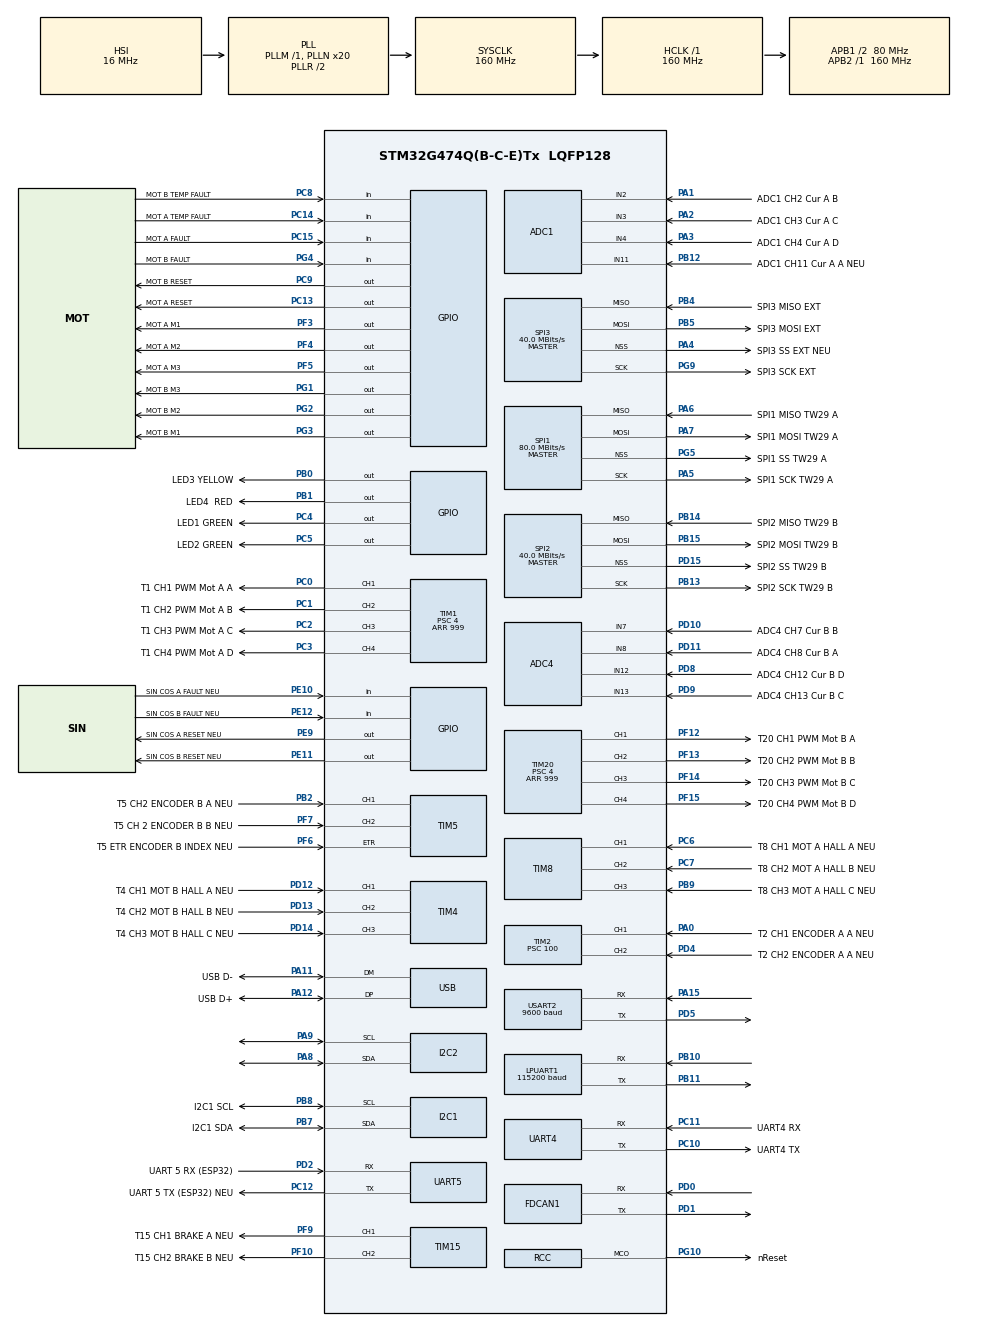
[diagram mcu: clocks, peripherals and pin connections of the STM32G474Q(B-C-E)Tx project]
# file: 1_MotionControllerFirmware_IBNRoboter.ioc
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ADC1.Channel-0\#ChannelRegularConversion=ADC_CHANNEL_2
ADC1.NbrOfConversionFlag=1
ADC1.OffsetNumber-0\#ChannelRegularConversion=ADC_OFFSET_NONE
ADC1.Rank-0\#ChannelRegularConversion=1
ADC1.SamplingTime-0\#ChannelRegularConversion=ADC_SAMPLETIME_2CYCLES_5
ADC1.master=1
ADC4.Channel-1\#ChannelRegularConversion=ADC_CHANNEL_12
ADC4.NbrOfConversionFlag=1
ADC4.OffsetNumber-1\#ChannelRegularConversion=ADC_OFFSET_NONE
ADC4.Rank-1\#ChannelRegularConversion=1
ADC4.SamplingTime-1\#ChannelRegularConversion=ADC_SAMPLETIME_2CYCLES_5
Dma.LPUART1_RX.0.Direction=DMA_PERIPH_TO_MEMORY
Dma.LPUART1_RX.0.EventEnable=DISABLE
Dma.LPUART1_RX.0.Instance=DMA1_Channel1
Dma.LPUART1_RX.0.MemDataAlignment=DMA_MDATAALIGN_BYTE
Dma.LPUART1_RX.0.MemInc=DMA_MINC_ENABLE
Dma.LPUART1_RX.0.Mode=DMA_NORMAL
Dma.LPUART1_RX.0.PeriphDataAlignment=DMA_PDATAALIGN_BYTE
Dma.LPUART1_RX.0.PeriphInc=DMA_PINC_DISABLE
Dma.LPUART1_RX.0.Polarity=HAL_DMAMUX_REQ_GEN_RISING
Dma.LPUART1_RX.0.Priority=DMA_PRIORITY_LOW
Dma.LPUART1_RX.0.RequestNumber=1
Dma.LPUART1_RX.0.SignalID=NONE
Dma.LPUART1_RX.0.SyncEnable=DISABLE
Dma.LPUART1_RX.0.SyncPolarity=HAL_DMAMUX_SYNC_NO_EVENT
Dma.LPUART1_RX.0.SyncRequestNumber=1
Dma.LPUART1_RX.0.SyncSignalID=NONE
Dma.LPUART1_TX.1.Direction=DMA_MEMORY_TO_PERIPH
Dma.LPUART1_TX.1.EventEnable=DISABLE
Dma.LPUART1_TX.1.Instance=DMA1_Channel2
Dma.LPUART1_TX.1.MemDataAlignment=DMA_MDATAALIGN_BYTE
Dma.LPUART1_TX.1.MemInc=DMA_MINC_ENABLE
Dma.LPUART1_TX.1.Mode=DMA_NORMAL
Dma.LPUART1_TX.1.PeriphDataAlignment=DMA_PDATAALIGN_BYTE
Dma.LPUART1_TX.1.PeriphInc=DMA_PINC_DISABLE
Dma.LPUART1_TX.1.Polarity=HAL_DMAMUX_REQ_GEN_RISING
Dma.LPUART1_TX.1.Priority=DMA_PRIORITY_LOW
Dma.LPUART1_TX.1.RequestNumber=1
Dma.LPUART1_TX.1.SignalID=NONE
Dma.LPUART1_TX.1.SyncEnable=DISABLE
Dma.LPUART1_TX.1.SyncPolarity=HAL_DMAMUX_SYNC_NO_EVENT
Dma.LPUART1_TX.1.SyncRequestNumber=1
Dma.LPUART1_TX.1.SyncSignalID=NONE
Dma.Request0=LPUART1_RX
Dma.Request1=LPUART1_TX
FDCAN1.AutoRetransmission=ENABLE
FDCAN1.CalculateBaudRateNominal=125000
FDCAN1.CalculateTimeBitNominal=8000
FDCAN1.CalculateTimeQuantumNominal=500.0
FDCAN1.DataPrescaler=10
FDCAN1.DataTimeSeg1=13
FDCAN1.DataTimeSeg2=2
FDCAN1.NominalPrescaler=40
FDCAN1.NominalTimeSeg1=13
FDCAN1.NominalTimeSeg2=2
FDCAN1.TransmitPause=ENABLE
FREERTOS.Tasks01=defaultTask,24,128,StartDefaultTask,Default,NULL,Dynamic,NULL,NULL;canopen,48,128,canopen_task,Default,NULL,Dynamic,NULL,NULL;IBNusbTaskHandl,8,128,startIBNusbTask,Default,NULL,Dynamic,NULL,NULL
FREERTOS.configTOTAL_HEAP_SIZE=10000
I2C1.Timing=0x10D19CE4
I2C2.Timing=0x10D19CE4
LPUART1.BaudRate=115200
Mcu.Family=STM32G4
Mcu.Name=STM32G474Q(B-C-E)Tx
Mcu.Package=LQFP128
NVIC.DMA1_Channel1_IRQn=true\:5\:0\:false\:false\:true\:true\:false\:true\:true
NVIC.DMA1_Channel2_IRQn=true\:5\:0\:false\:false\:true\:true\:false\:true\:true
NVIC.FDCAN1_IT0_IRQn=true\:5\:0\:false\:false\:true\:true\:true\:true\:true
NVIC.FDCAN1_IT1_IRQn=true\:5\:0\:false\:false\:true\:true\:true\:true\:true
NVIC.LPUART1_IRQn=true\:5\:0\:false\:false\:true\:true\:true\:true\:true
NVIC.PriorityGroup=NVIC_PRIORITYGROUP_4
NVIC.TIM1_TRG_COM_TIM17_IRQn=true\:5\:0\:true\:false\:true\:true\:true\:true\:true
NVIC.TIM1_UP_TIM16_IRQn=true\:5\:0\:false\:false\:true\:true\:true\:true\:true
NVIC.TIM3_IRQn=true\:5\:0\:true\:false\:true\:true\:true\:true\:true
NVIC.USB_HP_IRQn=true\:5\:0\:false\:false\:true\:true\:true\:true\:true
NVIC.USB_LP_IRQn=true\:5\:0\:false\:false\:true\:true\:false\:true\:true
PA0.GPIO_Label=T2 CH1 ENCODER A A NEU
PA0.Signal=S_TIM2_CH1
PA1.GPIO_Label=ADC1 CH2 Cur A B
PA1.Mode=IN2-Single-Ended
PA1.Signal=ADC1_IN2
PA11.GPIO_Label=USB D-
PA11.Mode=Device
PA11.Signal=USB_DM
PA12.GPIO_Label=USB D+
PA12.Mode=Device
PA12.Signal=USB_DP
PA13.GPIO_Label=SWD SWDIO
PA13.Mode=Serial_Wire
PA13.Signal=SYS_JTMS-SWDIO
PA14.GPIO_Label=SWD SWCLK
PA14.Mode=Serial_Wire
PA14.Signal=SYS_JTCK-SWCLK
PA15.Mode=Asynchronous
PA15.Signal=USART2_RX
PA2.GPIO_Label=ADC1 CH3 Cur A C
PA2.Mode=IN3-Single-Ended
PA2.Signal=ADC1_IN3
PA3.GPIO_Label=ADC1 CH4 Cur A D
PA3.Mode=IN4-Single-Ended
PA3.Signal=ADC1_IN4
PA4.GPIO_Label=SPI3 SS EXT NEU
PA4.Mode=NSS_Signal_Hard_Output
PA4.Signal=SPI3_NSS
PA5.GPIO_Label=SPI1 SCK TW29 A
PA5.Mode=Full_Duplex_Master
PA5.Signal=SPI1_SCK
PA6.GPIO_Label=SPI1 MISO TW29 A
PA6.Mode=Full_Duplex_Master
PA6.Signal=SPI1_MISO
PA7.GPIO_Label=SPI1 MOSI TW29 A
PA7.Mode=Full_Duplex_Master
PA7.Signal=SPI1_MOSI
PA8.Mode=I2C
PA8.Signal=I2C2_SDA
PA9.Mode=I2C
PA9.Signal=I2C2_SCL
PB0.GPIO_Label=LED3 YELLOW
PB0.Signal=GPIO_Output
PB1.GPIO_Label=LED4  RED
PB1.Signal=GPIO_Output
PB10.Mode=Asynchronous
PB10.Signal=LPUART1_RX
PB11.Mode=Asynchronous
PB11.Signal=LPUART1_TX
PB12.GPIO_Label=ADC1 CH11 Cur A A NEU
PB12.Mode=IN11-Single-Ended
PB12.Signal=ADC1_IN11
PB13.GPIO_Label=SPI2 SCK TW29 B
PB13.Mode=Full_Duplex_Master
PB13.Signal=SPI2_SCK
PB14.GPIO_Label=SPI2 MISO TW29 B
PB14.Mode=Full_Duplex_Master
PB14.Signal=SPI2_MISO
PB15.GPIO_Label=SPI2 MOSI TW29 B
PB15.Mode=Full_Duplex_Master
PB15.Signal=SPI2_MOSI
PB2.GPIO_Label=T5 CH2 ENCODER B A NEU
PB2.Signal=S_TIM5_CH1
PB3.Signal=SYS_JTDO-SWO
PB4.GPIO_Label=SPI3 MISO EXT
PB4.Mode=Full_Duplex_Master
PB4.Signal=SPI3_MISO
PB5.GPIO_Label=SPI3 MOSI EXT
PB5.Mode=Full_Duplex_Master
PB5.Signal=SPI3_MOSI
PB7.GPIO_Label=I2C1 SDA
PB7.Mode=I2C
PB7.Signal=I2C1_SDA
PB8-BOOT0.GPIO_Label=I2C1 SCL
PB8-BOOT0.Mode=I2C
PB8-BOOT0.Signal=I2C1_SCL
PB9.GPIO_Label=T8 CH3 MOT A HALL C NEU
PB9.Signal=S_TIM8_CH3
PC0.GPIO_Label=T1 CH1 PWM Mot A A
PC0.Signal=S_TIM1_CH1
PC1.GPIO_Label=T1 CH2 PWM Mot A B
PC1.Signal=S_TIM1_CH2
PC10.GPIO_Label=UART4 TX
PC10.Mode=Asynchronous
PC10.Signal=UART4_TX
PC11.GPIO_Label=UART4 RX
PC11.Mode=Asynchronous
PC11.Signal=UART4_RX
PC12.GPIO_Label=UART 5 TX (ESP32) NEU
PC12.Mode=Asynchronous
PC12.Signal=UART5_TX
PC13.GPIO_Label=MOT A RESET
PC13.Signal=GPIO_Output
PC14-OSC32_IN.GPIO_Label=MOT A TEMP FAULT
PC14-OSC32_IN.Signal=GPIO_Input
PC15-OSC32_OUT.GPIO_Label=MOT A FAULT
PC15-OSC32_OUT.Signal=GPIO_Input
PC2.GPIO_Label=T1 CH3 PWM Mot A C
PC2.Signal=S_TIM1_CH3
PC3.GPIO_Label=T1 CH4 PWM Mot A D
PC3.Signal=S_TIM1_CH4
PC4.GPIO_Label=LED1 GREEN
PC4.Signal=GPIO_Output
PC5.GPIO_Label=LED2 GREEN
PC5.Signal=GPIO_Output
PC6.GPIO_Label=T8 CH1 MOT A HALL A NEU
PC6.Signal=S_TIM8_CH1
PC7.GPIO_Label=T8 CH2 MOT A HALL B NEU
PC7.Signal=S_TIM8_CH2
PC8.GPIO_Label=MOT B TEMP FAULT
PC8.Signal=GPIO_Input
PC9.GPIO_Label=MOT B RESET
PC9.Signal=GPIO_Output
PD0.Mode=FDCAN_Activate
PD0.Signal=FDCAN1_RX
PD1.Mode=FDCAN_Activate
PD1.Signal=FDCAN1_TX
PD10.GPIO_Label=ADC4 CH7 Cur B B
PD10.Mode=IN7-Single-Ended
PD10.Signal=ADC4_IN7
PD11.GPIO_Label=ADC4 CH8 Cur B A
PD11.Mode=IN8-Single-Ended
PD11.Signal=ADC4_IN8
PD12.GPIO_Label=T4 CH1 MOT B HALL A NEU
PD12.Signal=S_TIM4_CH1
PD13.GPIO_Label=T4 CH2 MOT B HALL B NEU
PD13.Signal=S_TIM4_CH2
PD14.GPIO_Label=T4 CH3 MOT B HALL C NEU
PD14.Signal=S_TIM4_CH3
PD15.GPIO_Label=SPI2 SS TW29 B
PD15.Mode=NSS_Signal_Hard_Output
PD15.Signal=SPI2_NSS
PD2.GPIO_Label=UART 5 RX (ESP32)
PD2.Mode=Asynchronous
PD2.Signal=UART5_RX
PD3.Signal=S_TIM2_ETR
PD4.GPIO_Label=T2 CH2 ENCODER A A NEU
PD4.Signal=S_TIM2_CH2
PD5.Mode=Asynchronous
PD5.Signal=USART2_TX
PD8.GPIO_Label=ADC4 CH12 Cur B D
PD8.Mode=IN12-Single-Ended
PD8.Signal=ADC4_IN12
PD9.GPIO_Label=ADC4 CH13 Cur B C
PD9.Mode=IN13-Single-Ended
PD9.Signal=ADC4_IN13
PE10.GPIO_Label=SIN COS A FAULT NEU
PE10.Signal=GPIO_Input
PE11.GPIO_Label=SIN COS B RESET NEU
PE11.Signal=GPIO_Output
PE12.GPIO_Label=SIN COS B FAULT NEU
PE12.Signal=GPIO_Input
PE2.Signal=SYS_TRACECLK
PE3.Signal=SYS_TRACED0
PE4.Signal=SYS_TRACED1
PE5.Signal=SYS_TRACED2
PE6.Signal=SYS_TRACED3
PE9.GPIO_Label=SIN COS A RESET NEU
PE9.Signal=GPIO_Output
PF0-OSC_IN.GPIO_Label=HSE IN
PF0-OSC_IN.Mode=HSE-External-Oscillator
PF0-OSC_IN.Signal=RCC_OSC_IN
PF1-OSC_OUT.GPIO_Label=HSE OUT
PF1-OSC_OUT.Mode=HSE-External-Oscillator
PF1-OSC_OUT.Signal=RCC_OSC_OUT
PF10.GPIO_Label=T15 CH2 BRAKE B NEU
PF10.Signal=S_TIM15_CH2
PF12.GPIO_Label=T20 CH1 PWM Mot B A
PF12.GPIO_ModeDefaultPP=GPIO_MODE_AF_PP
PF12.GPIO_PuPd=GPIO_NOPULL
PF12.GPIO_Speed=GPIO_SPEED_FREQ_LOW
PF12.Signal=S_TIM20_CH1
PF13.GPIO_Label=T20 CH2 PWM Mot B B
PF13.GPIO_ModeDefaultPP=GPIO_MODE_AF_PP
PF13.GPIO_PuPd=GPIO_NOPULL
PF13.GPIO_Speed=GPIO_SPEED_FREQ_LOW
PF13.Signal=S_TIM20_CH2
PF14.GPIO_Label=T20 CH3 PWM Mot B C
PF14.GPIO_ModeDefaultPP=GPIO_MODE_AF_PP
PF14.GPIO_PuPd=GPIO_NOPULL
PF14.GPIO_Speed=GPIO_SPEED_FREQ_LOW
PF14.Signal=S_TIM20_CH3
PF15.GPIO_Label=T20 CH4 PWM Mot B D
PF15.GPIO_ModeDefaultPP=GPIO_MODE_AF_PP
PF15.GPIO_PuPd=GPIO_NOPULL
PF15.GPIO_Speed=GPIO_SPEED_FREQ_LOW
PF15.Signal=S_TIM20_CH4
PF3.GPIO_Label=MOT A M1
PF3.Signal=GPIO_Output
PF4.GPIO_Label=MOT A M2
PF4.Signal=GPIO_Output
PF5.GPIO_Label=MOT A M3
PF5.Signal=GPIO_Output
PF6.GPIO_Label=T5 ETR ENCODER B INDEX NEU
PF6.Signal=S_TIM5_ETR
PF7.GPIO_Label=T5 CH 2 ENCODER B B NEU
PF7.Signal=S_TIM5_CH2
PF9.GPIO_Label=T15 CH1 BRAKE A NEU
PF9.Signal=S_TIM15_CH1
PG1.GPIO_Label=MOT B M3
PG1.Signal=GPIO_Output
PG10-NRST.GPIO_Label=nReset
PG10-NRST.Mode=Clock-out
PG10-NRST.Signal=RCC_MCO
PG2.GPIO_Label=MOT B M2
PG2.Signal=GPIO_Output
PG3.GPIO_Label=MOT B M1
PG3.Signal=GPIO_Output
PG4.GPIO_Label=MOT B FAULT
PG4.Signal=GPIO_Input
PG5.GPIO_Label=SPI1 SS TW29 A
PG5.Mode=NSS_Signal_Hard_Output
PG5.Signal=SPI1_NSS
PG9.GPIO_Label=SPI3 SCK EXT
PG9.Mode=Full_Duplex_Master
PG9.Signal=SPI3_SCK
ProjectManager.HeapSize=0x200
ProjectManager.StackSize=0x400
ProjectManager.TargetToolchain=STM32CubeIDE
RCC.ADC12Freq_Value=160000000
RCC.ADC345Freq_Value=160000000
RCC.AHBFreq_Value=160000000
RCC.APB1CLKDivider=RCC_HCLK_DIV2
RCC.APB1Freq_Value=80000000
RCC.APB1TimFreq_Value=160000000
RCC.APB2Freq_Value=160000000
RCC.APB2TimFreq_Value=160000000
RCC.CK48CLockSelection=RCC_USBCLKSOURCE_HSI48
RCC.CortexFreq_Value=160000000
RCC.EXTERNAL_CLOCK_VALUE=12288000
RCC.HCLKFreq_Value=160000000
RCC.HSE_VALUE=48000000
RCC.HSI48_VALUE=48000000
RCC.HSI_VALUE=16000000
RCC.LSE_VALUE=32768
RCC.PLLN=20
RCC.PLLQ=RCC_PLLQ_DIV4
RCC.SYSCLKFreq_VALUE=160000000
RCC.SYSCLKSource=RCC_SYSCLKSOURCE_PLLCLK
RCC.USBFreq_Value=48000000
RCC.VCOOutputFreq_Value=320000000
SH.S_TIM15_CH1.0=TIM15_CH1,Output Compare1 CH1
SH.S_TIM15_CH2.0=TIM15_CH2,Output Compare2 CH2
SH.S_TIM1_CH1.0=TIM1_CH1,PWM Generation1 CH1
SH.S_TIM1_CH2.0=TIM1_CH2,PWM Generation2 CH2
SH.S_TIM1_CH3.0=TIM1_CH3,PWM Generation3 CH3
SH.S_TIM1_CH4.0=TIM1_CH4,PWM Generation4 CH4
SH.S_TIM20_CH1.0=TIM20_CH1,PWM Generation1 CH1
SH.S_TIM20_CH2.0=TIM20_CH2,PWM Generation2 CH2
SH.S_TIM20_CH3.0=TIM20_CH3,PWM Generation3 CH3
SH.S_TIM20_CH4.0=TIM20_CH4,PWM Generation4 CH4
SH.S_TIM2_CH1.0=TIM2_CH1,Encoder_Interface
SH.S_TIM2_CH2.0=TIM2_CH2,Encoder_Interface
SH.S_TIM2_ETR.0=TIM2_ETR
SH.S_TIM4_CH1.0=TIM4_CH1,Xored_Inputs_Hall_Sensor_Interface
SH.S_TIM4_CH2.0=TIM4_CH2,Xored_Inputs_Hall_Sensor_Interface
SH.S_TIM4_CH3.0=TIM4_CH3,Xored_Inputs_Hall_Sensor_Interface
SH.S_TIM5_CH1.0=TIM5_CH1,Encoder_Interface_w_index
SH.S_TIM5_CH2.0=TIM5_CH2,Encoder_Interface_w_index
SH.S_TIM5_ETR.0=TIM5_ETR,Encoder_Interface_w_index
SH.S_TIM8_CH1.0=TIM8_CH1,Xored_Inputs_Hall_Sensor_Interface
SH.S_TIM8_CH2.0=TIM8_CH2,Xored_Inputs_Hall_Sensor_Interface
SH.S_TIM8_CH3.0=TIM8_CH3,Xored_Inputs_Hall_Sensor_Interface
SPI1.BaudRatePrescaler=SPI_BAUDRATEPRESCALER_2
SPI1.CalculateBaudRate=80.0 MBits/s
SPI1.Direction=SPI_DIRECTION_2LINES
SPI1.Mode=SPI_MODE_MASTER
SPI1.VirtualNSS=VM_NSSHARD
SPI1.VirtualType=VM_MASTER
SPI2.BaudRatePrescaler=SPI_BAUDRATEPRESCALER_2
SPI2.CalculateBaudRate=40.0 MBits/s
SPI2.Direction=SPI_DIRECTION_2LINES
SPI2.Mode=SPI_MODE_MASTER
SPI2.VirtualNSS=VM_NSSHARD
SPI2.VirtualType=VM_MASTER
SPI3.BaudRatePrescaler=SPI_BAUDRATEPRESCALER_2
SPI3.CalculateBaudRate=40.0 MBits/s
SPI3.Direction=SPI_DIRECTION_2LINES
SPI3.Mode=SPI_MODE_MASTER
SPI3.VirtualNSS=VM_NSSHARD
SPI3.VirtualType=VM_MASTER
TIM1.AutoReloadPreload=TIM_AUTORELOAD_PRELOAD_DISABLE
TIM1.Channel-PWM\ Generation1\ CH1=TIM_CHANNEL_1
TIM1.Channel-PWM\ Generation2\ CH2=TIM_CHANNEL_2
TIM1.Channel-PWM\ Generation3\ CH3=TIM_CHANNEL_3
TIM1.Channel-PWM\ Generation4\ CH4=TIM_CHANNEL_4
TIM1.PeriodNoDither=999
TIM1.Prescaler=4
TIM15.Channel-Output\ Compare1\ CH1=TIM_CHANNEL_1
TIM15.Channel-Output\ Compare2\ CH2=TIM_CHANNEL_2
TIM16.PeriodNoDither=1000
TIM16.Prescaler=63
TIM17.AutoReloadPreload=TIM_AUTORELOAD_PRELOAD_ENABLE
TIM17.PeriodNoDither=1000
TIM17.Prescaler=16
TIM2.CounterMode=TIM_COUNTERMODE_DOWN
TIM2.EncoderMode=TIM_ENCODERMODE_TI12
TIM2.Prescaler=100
TIM20.AutoReloadPreload=TIM_AUTORELOAD_PRELOAD_ENABLE
TIM20.Channel-PWM\ Generation1\ CH1=TIM_CHANNEL_1
TIM20.Channel-PWM\ Generation2\ CH2=TIM_CHANNEL_2
TIM20.Channel-PWM\ Generation3\ CH3=TIM_CHANNEL_3
TIM20.Channel-PWM\ Generation4\ CH4=TIM_CHANNEL_4
TIM20.PeriodNoDither=999
TIM20.Prescaler=4
TIM3.PeriodNoDither=63
TIM3.Prescaler=256
USART2.BaudRate=9600
USART2.OverrunDisableParam=ADVFEATURE_OVERRUN_DISABLE
USART2.VirtualMode-Asynchronous=VM_ASYNC
USB_DEVICE.CLASS_NAME_FS=CDC
USB_DEVICE.USBD_LPM_ENABLED=0
USB_DEVICE.VirtualMode=Cdc
USB_DEVICE.VirtualModeFS=Cdc_FS
VP_FREERTOS_VS_CMSIS_V2.Mode=CMSIS_V2
VP_SYS_VS_DBSignals.Mode=DisableDeadBatterySignals
VP_TIM16_VS_ClockSourceINT.Mode=Enable_Timer
VP_TIM17_VS_ClockSourceINT.Mode=Enable_Timer
VP_TIM3_VS_ClockSourceINT.Mode=Internal
VP_TIM6_VS_ClockSourceINT.Mode=Enable_Timer
VP_USB_DEVICE_VS_USB_DEVICE_CDC_FS.Mode=CDC_FS
board=custom

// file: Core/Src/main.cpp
/* USER CODE BEGIN Header */
/**
  ******************************************************************************
  * @file           : main.c
  * @brief          : Main program body
  ******************************************************************************
  * @attention
  *
  * Copyright (c) 2025 STMicroelectronics.
  * All rights reserved.
  *
  * This software is licensed under terms that can be found in the LICENSE file
  * in the root directory of this software component.
  * If no LICENSE file comes with this software, it is provided AS-IS.
  *
  ******************************************************************************
  */
/* USER CODE END Header */
#include "main.h"
#include "cmsis_os.h"
#include "adc.h"
#include "dma.h"
#include "fdcan.h"
#include "i2c.h"
#include "usart.h"
#include "spi.h"
#include "tim.h"
#include "usb_device.h"
#include "gpio.h"

/* USER CODE BEGIN Includes */
#include "usbd_cdc_if.h"
#include <stdint.h>
#include "typedefs.h"
#include "commando_interpreter.h"
#include "app_freertos.h"
#include "monitor.h"
#include <stdbool.h>
#include "CO_app_STM32.h"
#include "OD.h"

/* USER CODE END Includes */

/* USER CODE BEGIN PV */
TIM_OC_InitTypeDef sEmulConfigOC;

char cmd_str[CMD_STR_LENGTH] = {0};
bool new_cmd = false;

uint8_t axis_to_run = 0;
uint64_t servo_cnt = 0;

int32_t joint1_old = 0;
int32_t joint2_old = 0;

volatile float convVal1 = 0;
volatile float convVal2 = 0;
volatile float convVal3 = 0;

// Global class pointer for timer interrupt handler
axis_class* 				myAxis_ptr[MAX_NUM_AXIS];
data_recorder_class*		myDR_ptr;
PID_class*					myPID_pos_ptr[MAX_NUM_AXIS];
current_control_class*		myCurrent_Control[MAX_NUM_AXIS];
set_pwm_class*				myPWM_ptr[MAX_NUM_AXIS];

/* USER CODE END PV */

void SystemClock_Config(void);
void MX_FREERTOS_Init(void);
/* USER CODE BEGIN PFP */
//void send_string_DMA(const uint8_t* str);
void send_string_USB(const char* str, bool new_line);
/* USER CODE END PFP */

/* USER CODE BEGIN 0 */

axis_class 				myAxis[MAX_NUM_AXIS];
set_pwm_class			myPWM[MAX_NUM_AXIS];

error_class 				myError;

parameter_class 			myParameter;

ComInt_class 			com_inter(&myError);

// Classes belonging to axis
trajectory_class 		trajectory[MAX_NUM_AXIS];
pos_sensor_class		pos_sensor[MAX_NUM_AXIS];
PID_class				pid_pos[MAX_NUM_AXIS];
current_control_class 	current_control[MAX_NUM_AXIS];

// Data recorder
data_recorder_class 		myDR(&myParameter,&myError);

/* USER CODE END 0 */

int main(void)
{

  /* USER CODE BEGIN 1 */
	SCB->VTOR = 0x08000000;

  /* USER CODE END 1 */

  /* MCU Configuration--------------------------------------------------------*/

  /* Reset of all peripherals, Initializes the Flash interface and the Systick. */
  HAL_Init();

  /* Configure the system clock */
  SystemClock_Config();

  /* USER CODE BEGIN SysInit */

  MX_USB_Device_Init();

  /* USER CODE END SysInit */

  /* Initialize all configured peripherals */
  MX_GPIO_Init();
  MX_DMA_Init();
  MX_ADC1_Init();
  MX_ADC4_Init();
  MX_FDCAN1_Init();
  MX_I2C1_Init();
  MX_SPI1_Init();
  MX_SPI2_Init();
  MX_SPI3_Init();
  MX_TIM2_Init();
  MX_TIM5_Init();
  MX_TIM20_Init();
  MX_UART4_Init();
  MX_TIM4_Init();
  MX_TIM8_Init();
  MX_TIM15_Init();
  MX_UART5_Init();
  MX_TIM3_Init();
  MX_TIM17_Init();
  MX_TIM16_Init();
  MX_USART2_UART_Init();
  MX_TIM1_Init();
  MX_I2C2_Init();
  MX_TIM6_Init();
  MX_LPUART1_UART_Init();

  /* USER CODE BEGIN 2 */

  // not for USB: HAL_UART_Receive_DMA(&hlpuart1, rx_buff, 1);
	myParameter.myError		= &myError;
	myDR_ptr 				= &myDR;	// pointer only for debug reason
	com_inter.myDR 			= &myDR;
	com_inter.myParameter	= &myParameter;

   // Initialization of axis modules
   for(uint8_t i=0;i<MAX_NUM_AXIS;i++)
   {
 	  pid_pos[i].init(&myAxis[i],&myParameter,&myError);
 	  trajectory[i].init(&myAxis[i],&myParameter,&myError);
 	  pos_sensor[i].init(&myAxis[i],&myParameter,&myError);
 	  current_control[i].init(&myAxis[i],&myParameter,&myError, &myPWM[i],&trajectory[i]);
 	  // pointer to classes belonging to an Axis:
 	  myAxis[i].init(i,&myError,&trajectory[i],&pos_sensor[i],&pid_pos[i],&current_control[i],&myDR,&myParameter);

 	  current_control[i].init(&myAxis[i],&myParameter,&myError, &myPWM[i], &trajectory[i]); // second init with konown axes

 	  myAxis_ptr[i] 			= &myAxis[i];
 	  com_inter.myAxis[i] 		= myAxis_ptr[i];
 	  myDR.myAxis[i] 			= myAxis_ptr[i];

 	 myPID_pos_ptr[i] = &pid_pos[i];
 	 myCurrent_Control[i] = &current_control[i];
   }

   myDR.init();

  //send_string_DMA("Startup Controller...");
  //send_string_USB("Startup Controller...", true);

   myAxis[1].enabled = true;
   myPID_pos_ptr[1]->servo_on_off(true);

   myAxis[0].enabled = true;
   myPID_pos_ptr[0]->servo_on_off(true);

   HAL_TIM_Base_Start_IT(&htim3);

  /* USER CODE END 2 */

  /* Init scheduler */
  osKernelInitialize();

  /* Call init function for freertos objects (in cmsis_os2.c) */
  MX_FREERTOS_Init();

  /* Start scheduler */
  osKernelStart();

  /* We should never get here as control is now taken by the scheduler */

  /* Infinite loop */
  /* USER CODE BEGIN WHILE */

  while(1){

	  if(new_cmd == 1)
	  	{
	  	  // execute CMD
	  	  com_inter.interpreter(&cmd_str[0]);

	  	  new_cmd = 0;
	  	}

  }
    /* USER CODE END WHILE */

}

void SystemClock_Config(void)
{
  RCC_OscInitTypeDef RCC_OscInitStruct = {0};
  RCC_ClkInitTypeDef RCC_ClkInitStruct = {0};

  /** Configure the main internal regulator output voltage
  */
  HAL_PWREx_ControlVoltageScaling(PWR_REGULATOR_VOLTAGE_SCALE1_BOOST);

  /** Initializes the RCC Oscillators according to the specified parameters
  * in the RCC_OscInitTypeDef structure.
  */
  RCC_OscInitStruct.OscillatorType = RCC_OSCILLATORTYPE_HSI|RCC_OSCILLATORTYPE_HSI48;
  RCC_OscInitStruct.HSIState = RCC_HSI_ON;
  RCC_OscInitStruct.HSICalibrationValue = RCC_HSICALIBRATION_DEFAULT;
  RCC_OscInitStruct.HSI48State = RCC_HSI48_ON;
  RCC_OscInitStruct.PLL.PLLState = RCC_PLL_ON;
  RCC_OscInitStruct.PLL.PLLSource = RCC_PLLSOURCE_HSI;
  RCC_OscInitStruct.PLL.PLLM = RCC_PLLM_DIV1;
  RCC_OscInitStruct.PLL.PLLN = 20;
  RCC_OscInitStruct.PLL.PLLP = RCC_PLLP_DIV2;
  RCC_OscInitStruct.PLL.PLLQ = RCC_PLLQ_DIV4;
  RCC_OscInitStruct.PLL.PLLR = RCC_PLLR_DIV2;
  if (HAL_RCC_OscConfig(&RCC_OscInitStruct) != HAL_OK)
  {
    Error_Handler();
  }

  /** Initializes the CPU, AHB and APB buses clocks
  */
  RCC_ClkInitStruct.ClockType = RCC_CLOCKTYPE_HCLK|RCC_CLOCKTYPE_SYSCLK
                              |RCC_CLOCKTYPE_PCLK1|RCC_CLOCKTYPE_PCLK2;
  RCC_ClkInitStruct.SYSCLKSource = RCC_SYSCLKSOURCE_PLLCLK;
  RCC_ClkInitStruct.AHBCLKDivider = RCC_SYSCLK_DIV1;
  RCC_ClkInitStruct.APB1CLKDivider = RCC_HCLK_DIV2;
  RCC_ClkInitStruct.APB2CLKDivider = RCC_HCLK_DIV1;

  if (HAL_RCC_ClockConfig(&RCC_ClkInitStruct, FLASH_LATENCY_4) != HAL_OK)
  {
    Error_Handler();
  }
  HAL_RCC_MCOConfig(RCC_MCO_PG10, RCC_MCO1SOURCE_HSI, RCC_MCODIV_1);
}

/* USER CODE BEGIN 4 */

/**
  * @brief  Period elapsed callback in non-blocking mode
  * @param  htim TIM handle
  * @retval None
  */
__weak void HAL_TIM_PeriodElapsedCallback(TIM_HandleTypeDef *htim)
{
  /* Prevent unused argument(s) compilation warning */

	if (htim->Instance == TIM7) {
			HAL_IncTick();
		}

	// Handle CANOpen app interrupts
	if (htim == canopenNodeSTM32->timerHandle) {
		canopen_app_interrupt();
	}

	if (htim->Instance == TIM3) {
		// counter (Servo Loop)
		servo_cnt++;

		// jump between axes
		axis_to_run = (axis_to_run + 1) % MAX_NUM_AXIS;

		// run axis if pointer is valid
		if (axis_to_run < MAX_NUM_AXIS && myAxis_ptr[axis_to_run]) {
			// CANopen Daten
			if(axis_to_run == 0 && (joint1_old != OD_PERSIST_COMM.x6001_joint1))
			{
				myAxis_ptr[axis_to_run]->myTrajectory->setpoint = (OD_PERSIST_COMM.x6001_joint1/1000000.0)*5.0;//*10.0;//*5.0; // M1 Faktor 5.0
				joint1_old = OD_PERSIST_COMM.x6001_joint1;
			}

			if(axis_to_run == 1 && (joint2_old != OD_PERSIST_COMM.x6002_joint2))
			{
				myAxis_ptr[axis_to_run]->myTrajectory->setpoint = (OD_PERSIST_COMM.x6002_joint2/1000000.0)*-5.0;//*10.0;//*5.0; // M1 Faktor 5.0
				joint2_old = OD_PERSIST_COMM.x6002_joint2;
			}

			myAxis_ptr[axis_to_run]->run();

			// calculate servoload if TIM4 is initialized and constant is valid
			#ifdef TIMER_COUTER_MAX
			if (TIMER_COUTER_MAX > 0) {
				myAxis_ptr[axis_to_run]->servoload = (TIM4->CNT * 100) / TIMER_COUTER_MAX;
			}
			#endif
		}

		// run data recorder if pointer is valid
		if (myDR_ptr) {
			myDR_ptr->run();
		}
	}

  /* NOTE : This function should not be modified, when the callback is needed,
            the HAL_TIM_PeriodElapsedCallback could be implemented in the user file
   */
}

/* USER CODE END 4 */

void Error_Handler(void)
{
  /* USER CODE BEGIN Error_Handler_Debug */
  /* User can add his own implementation to report the HAL error return state */
  __disable_irq();
  while (1)
  {
	  /*
	  // Überprüfe auf Überhitzung oder Fehler
	  if (HAL_GPIO_ReadPin(GPIOC, GPIO_PIN_14) == GPIO_PIN_RESET) {
		  // Überhitzung
	  }
	  if (HAL_GPIO_ReadPin(GPIOC, GPIO_PIN_15) == GPIO_PIN_RESET) {
		  // Fehler
	  }

	//Driver B
	if (HAL_GPIO_ReadPin(GPIOC, GPIO_PIN_8) == GPIO_PIN_RESET) {
			// Überhitzung
		}
		if (HAL_GPIO_ReadPin(GPIOG, GPIO_PIN_4) == GPIO_PIN_RESET) {
			// Fehler
		}
	  }
	*/
  }
  /* USER CODE END Error_Handler_Debug */
}

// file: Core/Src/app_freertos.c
/* USER CODE BEGIN Header */
/**
  ******************************************************************************
  * File Name          : app_freertos.c
  * Description        : Code for freertos applications
  ******************************************************************************
  * @attention
  *
  * Copyright (c) 2025 STMicroelectronics.
  * All rights reserved.
  *
  * This software is licensed under terms that can be found in the LICENSE file
  * in the root directory of this software component.
  * If no LICENSE file comes with this software, it is provided AS-IS.
  *
  ******************************************************************************
  */
/* USER CODE END Header */

#include "FreeRTOS.h"
#include "task.h"
#include "main.h"
#include "cmsis_os.h"

#include "usb_device.h"

/* USER CODE BEGIN Includes */
#include "app_freertos.h"

#include "CO_app_STM32.h"
#include "fdcan.h"
#include "tim.h"

/* USER CODE END Includes */

/* Definitions for defaultTask */
osThreadId_t defaultTaskHandle;
const osThreadAttr_t defaultTask_attributes = {
  .name = "defaultTask",
  .priority = (osPriority_t) osPriorityNormal,
  .stack_size = 128 * 4
};
/* Definitions for canopen */
osThreadId_t canopenHandle;
const osThreadAttr_t canopen_attributes = {
  .name = "canopen",
  .priority = (osPriority_t) osPriorityRealtime,
  .stack_size = 128 * 4
};
/* Definitions for IBNusbTaskHandl */
osThreadId_t IBNusbTaskHandlHandle;
const osThreadAttr_t IBNusbTaskHandl_attributes = {
  .name = "IBNusbTaskHandl",
  .priority = (osPriority_t) osPriorityLow,
  .stack_size = 128 * 4
};

void StartDefaultTask(void *argument);
void canopen_task(void *argument);
void startIBNusbTask(void *argument);

void MX_FREERTOS_Init(void); /* (MISRA C 2004 rule 8.1) */

void MX_FREERTOS_Init(void) {

  /* Create the thread(s) */
  /* creation of defaultTask */
  defaultTaskHandle = osThreadNew(StartDefaultTask, NULL, &defaultTask_attributes);

  /* creation of canopen */
  canopenHandle = osThreadNew(canopen_task, NULL, &canopen_attributes);

  /* creation of IBNusbTaskHandl */
  IBNusbTaskHandlHandle = osThreadNew(startIBNusbTask, NULL, &IBNusbTaskHandl_attributes);

}

void StartDefaultTask(void *argument)
{
  /* init code for USB_Device */
  MX_USB_Device_Init();
  /* USER CODE BEGIN StartDefaultTask */
  /* Infinite loop */
  for(;;)
  {

	  //test_monitor();
	  osDelay(1);

  }
  /* USER CODE END StartDefaultTask */
}

void canopen_task(void *argument)
{
  /* USER CODE BEGIN canopen_task */
	CANopenNodeSTM32 canopenNodeSTM32;
	canopenNodeSTM32.CANHandle = &hfdcan1;
	canopenNodeSTM32.HWInitFunction = MX_FDCAN1_Init;
	canopenNodeSTM32.timerHandle = &htim17;
	canopenNodeSTM32.desiredNodeID = 2;
	canopenNodeSTM32.baudrate = 125;
	canopen_app_init(&canopenNodeSTM32);
	/* Infinite loop */
	for(;;)
	{
		//Reflect CANopenStatus on LEDs
	  //HAL_GPIO_WritePin(LED1_GPIO_Port, LED1_Pin, !canOpenNodeSTM32.outStatusLEDGreen);
	  //HAL_GPIO_WritePin(LED2_GPIO_Port, LED2_Pin, !canOpenNodeSTM32.outStatusLEDRed);
	  HAL_GPIO_TogglePin(LED1_GREEN_GPIO_Port, LED1_GREEN_Pin);
	  osDelay(300);
	  canopen_app_process();
	  // Sleep for 1ms, you can decrease it if required, in the canopen_app_process we will double check to make sure 1ms passed
	  vTaskDelay(pdMS_TO_TICKS(1));
	}
  /* USER CODE END canopen_task */
}

void startIBNusbTask(void *argument)
{
  /* USER CODE BEGIN startIBNusbTask */
  /* Infinite loop */
  for(;;)
  {
	  run_monitor();
    osDelay(100);
  }
  /* USER CODE END startIBNusbTask */
}
